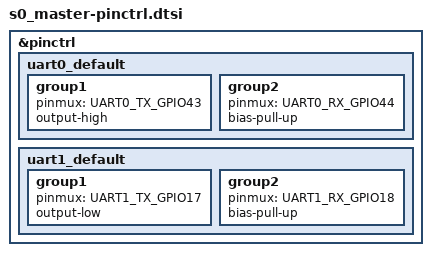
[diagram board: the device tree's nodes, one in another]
/*
 * SPDX-License-Identifier: Apache-2.0
 */

#include <zephyr/dt-bindings/pinctrl/esp-pinctrl-common.h>
#include <zephyr/dt-bindings/pinctrl/esp32s3-pinctrl.h>
#include <zephyr/dt-bindings/pinctrl/esp32s3-gpio-sigmap.h>

&pinctrl {
	/* Console on the 4-pin DEBUG header (J3: 3V3, RXD0, TXD0, GND) */
	uart0_default: uart0_default {
		group1 {
			pinmux = <UART0_TX_GPIO43>;
			output-high;
		};

		group2 {
			pinmux = <UART0_RX_GPIO44>;
			bias-pull-up;
		};
	};

	/* RS-485 transceiver: GPIO17 -> D, GPIO18 <- R */
	uart1_default: uart1_default {
		group1 {
			pinmux = <UART1_TX_GPIO17>;
			/* the transmitter is inverted, so idle is low */
			output-low;
		};

		group2 {
			pinmux = <UART1_RX_GPIO18>;
			bias-pull-up;
		};
	};
};
